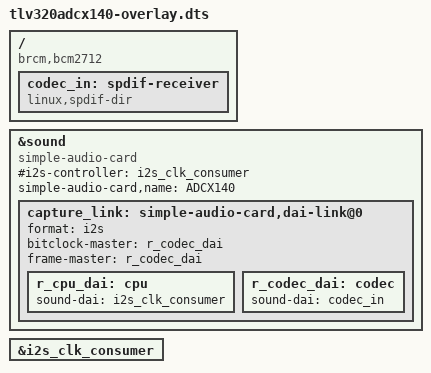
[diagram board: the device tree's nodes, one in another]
//Device tree overlay for TLV320adcx140 using the simple-audio-card in slave mode

/dts-v1/;
/plugin/;



/ {
    compatible = "brcm,bcm2712";

    fragment@0 {
        target = <&sound>;
        __overlay__ {
            compatible = "simple-audio-card";
            #i2s-controller = <&i2s_clk_consumer>;
            simple-audio-card,name = "ADCX140";
            status="okay";
    

            capture_link: simple-audio-card,dai-link@0 {
                format = "i2s";

                // Set RasPi to I2S slave
                bitclock-master = <&r_codec_dai>;
                frame-master = <&r_codec_dai>;

                r_cpu_dai: cpu {
                    sound-dai = <&i2s_clk_consumer>;

                // TDM slot configuration for stereo
                //    dai-tdm-slot-num = <2>;
                //    dai-tdm-slot-width = <16>;
                };

                r_codec_dai: codec {
                    sound-dai = <&codec_in>;
                };
            };

            
        };
    };

    fragment@1 {
        target-path = "/";
        __overlay__ {
            
            codec_in: spdif-receiver {
                #address-cells = <0>;
                #size-cells = <0>;
                #sound-dai-cells = <0>;
                

                compatible = "linux,spdif-dir";

                status = "okay";
            };
        };
    };

    fragment@2 {
        target = <&i2s_clk_consumer>;
        __overlay__ {
            #sound-dai-cells = <0>;
            status = "okay";
        };
    };
    
    
};
